# psoc4hvpaspm10 register map
Vendor: Infineon Technologies; Series: PSOC4HVPASPM10; File version: 1.0
CPU: CM0PLUS r0p1, little endian, MPU, no FPU, VTOR, 2 interrupt priority bits, 32 interrupts
Registers are 32-bit, read-write, reset 0x0 unless marked. A register's access mark holds for its fields unless they carry their own. Offsets are from the block's base; [hi:lo] are bit positions; lines under a group give offsets from that group; {n}, {i} and the like mark numbered series.

## LIN0 — LIN
Base 0x402D0000
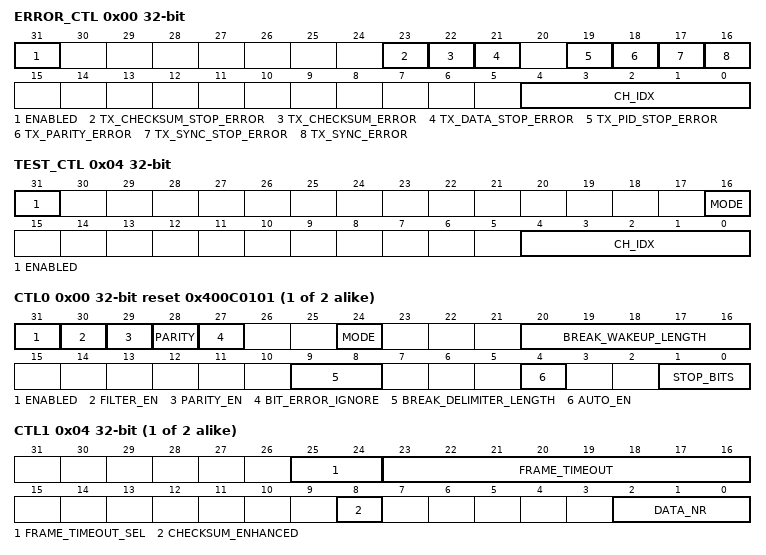
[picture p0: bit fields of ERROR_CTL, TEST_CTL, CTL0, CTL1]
0x00 ERROR_CTL — Error control
  [31] ENABLED — Error injection enable: '0': Disabled. '1': Enabled.
  [23] TX_CHECKSUM_STOP_ERROR — The checksum field STOP bits are inverted to '0'. At the receiver, this should result in INTR.RX_RESPONSE_FRAME_ERROR activation.
  [22] TX_CHECKSUM_ERROR — The checksum field is inverted. At the receiver, this should result in INTR.RX_RESPONSE_CHECKSUM_ERROR activation.
  [21] TX_DATA_STOP_ERROR — The data field STOP bits are inverted to '0'. At the receiver, this should result in INTR.RX_RESPONSE_FRAME_ERROR activation. Note: Used in UART mode.
  [19] TX_PID_STOP_ERROR — The PID field STOP bits are inverted to '0'. At the receiver, this should result in INTR.RX_HEADER_FRAME_ERROR activation.
  [18] TX_PARITY_ERROR — In LIN mode, the PID parity bit P[1] is inverted from !(ID[5] ^ ID[4] ^ ID[3] ^ ID[1]) to (ID[5] ^ ID[4] ^ ID[3] ^ ID[1]). At the receiver, this should result in INTR.RX_HEADER_PARITY_ERROR activation. In UART mode, a data field's parity bit is inverted.
  [17] TX_SYNC_STOP_ERROR — The synchronization field STOP bits are inverted to '0'. At the receiver, this should result in INTR.RX_HEADER_SYNC_ERROR or INTR.RX_HEADER_FRAME_ERROR activation.
  [16] TX_SYNC_ERROR — The synchronization field is changed from 0x55 to 0x00. At the receiver, this should result in INTR.RX_HEADER_SYNC_ERROR activation.
  [4:0] CH_IDX — Specifies the channel index of the channel to which HW injected channel transmitter errors applies.
0x04 TEST_CTL — Test control
  [31] ENABLED — Test enable: '0': Disabled. Functional mode. - tx_in[CH_IDX] = IOSS lin_tx_in[CH_IDX]. - tx_in[CH_NR-1] = IOSS lin_tx_in[CH_NR-1]. - rx_in[CH_IDX] = IOSS lin_rx_in[CH_IDX]. - rx_in[CH_NR-1] = IOSS lin_rx_in[CH_NR-1]. - lin_tx_out[CH_IDX] = tx_out[CH_IDX]. - lin_tx_out[CH_NR-1] = tx_out[CH_NR-1]. '1': Enabled. Test mode, specific test mode is specified by MODE.
  [16] MODE — Test mode: '0': Partial disconnect from IOSS. This mode's isolation allows for device test without relying on an external LIN transceiver. The IOSS 'tx' IO cell can be used to observe messages outside of the device. - tx_in[CH_IDX] = IOSS lin_tx_in[CH_IDX]. - tx_in[CH_NR-1] = IOSS lin_tx_in[CH_IDX]. - rx_in[CH_IDX] = IOSS lin_tx_in[CH_IDX]. - rx_in[CH_NR-1] = IOSS lin_tx_in[CH_IDX]. - lin_tx_out[CH_IDX] = tx_out[CH_IDX] & tx_out[CH_NR-1]. - lin_tx_out[CH_NR-1] = tx_out[CH_IDX] & tx_out[CH_NR-1]. '1': Full disconnect from IOSS (the IOSS/HSIOM should disconnect 'tx_out' from the 'tx' IO cell). This mode's isolation allows for device test without effecting an operational LIN cluster. - tx_in[CH_IDX] = lin_tx_out[CH_IDX]. - tx_in[CH_NR-1] = lin_tx_out[CH_IDX]. - rx_in[CH_IDX] = lin_tx_out[CH_IDX]. - rx_in[CH_NR-1] = lin_tx_out[CH_IDX]. - lin_tx_out[CH_IDX] = tx_out[CH_IDX] & tx_out[CH_NR-1]. - lin_tx_out[CH_NR-1] = tx_out[CH_IDX] & tx_out[CH_NR-1].
  [4:0] CH_IDX — Specifies the channel index of the channel to which test applies. The channel IO signals of channel indices CH_IDX and CH_NR-1 are connected as specified by MODE. CH_IDX should be in the range [0, CH_NR-2], as channel index CH_NR-1 is always involved in test and cannot be connected to itself. The test mode allows BOTH of the two connected channels to be tested. Note: this testing functionality simplifies SW development, but may also be used in the field to verify correct channel functionality.
{0x8000+0x100*i} CH[{i}] (i=0..1) group — LIN channel structure
  0x00 CTL0 reset 0x400C0101 — Control 0
    [31] ENABLED — Channel enable: '0': Disabled. If a channel is disabled, all non-retained MMIO registers (e.g. the TX_RX_STATUS, and INTR registers) have their fields reset to their default value. '1': Enabled.
    [30] FILTER_EN — RX filter (for 'lin_rx_in'): '0': No filter. '1': Median 3 (default value) operates on the last three 'lin_rx_in' values. The sequences '000', '001', '010' and '100' result in a filtered value '0'. The sequences '111', '110', '101' and '011' result in a filtered value '1'.
    [29] PARITY_EN — Parity generation enable: '0': Disabled. No parity bit is transferred. '1': Enabled. The parity bit is transferred after the last (most significant) data field bit. Note: Used in UART mode only.
    [28] PARITY — Parity mode: '0': Even parity: even number of '1' bits (including parity). '1': Odd parity. Note: Used in UART mode only.
    [27] BIT_ERROR_IGNORE — Specifies behavior on a detected bit error during header or response transmission: '0': Message transfer is aborted. '1': Message transfer is NOT aborted. Note: this field does NOT effect the reporting of the bit error through INTR/STATUS.TX_HEADER/RESPONSE_BIT_ERROR; i.e. bit errors are always reported.
    [24] MODE — Mode of operation: '0': LIN mode. '1': UART mode.
      0=LIN (LIN mode.); 1=UART (UART mode.)
    [20:16] BREAK_WAKEUP_LENGTH — Break/wakeup length (minus 1) in bit periods: '0': 1 bit period. ... '10': 11 bit periods (break length for slave nodes) ... '12': 13 bit periods (break length for master nodes) ... '30': 31 bit periods. '31': Illegal (should NOT be used!!!) This field is used for transmission/reception of BOTH break and wakeup signals. Note that these functions are mutually exclusive: - When CMD.TX_HEADER is '1', the field specifies the transmitted break field. - When CMD.TX_WAKEUP is '1', the field specifies the transmitted wakeup field. - When CMD.RX_HEADER is '1', the field specifies the to be received break field. - Otherwise, the field specifies the to be received wakeup field. Per the standard, the master wakeup duration is between 250 us and 5 ms. To support uncalibrated slaves, a slave has a detection threshold of 150 us (3 bit periods at 20 kbps). After transmission of a break or wakeup signal, the INTR.TX_BREAK_WAKEUP_DONE interrupt cause is activated. After reception of a wakeup signal, the INTR.RX_BREAK_WAKEUP_DONE interrupt cause is activated. To specify longer wakeup signals in terms of absolute time (us/ms rather than bit periods), the associated PERI clock divider value can be (temporarily) increased to make the LIN bit period longer. Note: entering bus sleep mode is achieved with the 'go-to-sleep' command.
    [9:8] BREAK_DELIMITER_LENGTH — In LIN mode, this field specifies the break delimiter length: (used in header transmission, not used in header reception). '0': 1 bit period. '1': 2 bit periods (default value). '2': 3 bit periods. '3': 4 bit periods. In UART mode, this field specifies the data field size: '0': 5 bit data field. '1': 6 bit data field. '2': 7 bit data field. '3': 8 bit data field. When the data field size is less than 8 bits, the most significant (unused) bits of the DATAx.DATAy[7:0] fields should be set to '0' for the transmitter.
    [4] AUTO_EN — LIN transceiver auto enable: '0': Disabled. '1': Enabled. The TX_RX_STATUS.EN_OUT field is controlled by HW.
    [1:0] STOP_BITS — STOP bit periods: '0': 1/2 bit period. '1': 1 bit period. '2': 1 1/2 bit period. '3': 2 bit periods. In LIN mode, this field should be set to '1' (the default value) . In UART mode, this field can be programmed as desired. Note: receiver STOP bit frame errors can only be detected if the number of STOP bit periods is 1 or more bit period.
  0x04 CTL1 (reset mask 0x3000000) — Control 1
    [25:24] FRAME_TIMEOUT_SEL — Specifies the frame timeout mode: '0': No timeout functionality (default value). '1': Frame mode: detects timeout from the start of break field to checksum field STOP bits (inclusive). The minimum FRAME_TIMEOUT value is 34+20 bit periods (header and a response with 1 data field). '2': Frame header mode: detects timeout from the start of break field to PID field STOP bits (inclusive). The minimum FRAME_TIMEOUT value is 34 bit periods (header). '3': Frame response mode: detects timeout from the PID field STOP bits (exclusive) to checksum field STOP bits (the response space is included in the frame response). The minimum FRAME_TIMEOUT value is 20 bit periods (response with 1 data field).
    [23:16] FRAME_TIMEOUT — Specifies the maximum allowed length (timeout value) for a frame, frame header or frame response in bit periods. The LIN specification prescribes to set the maximum length to 1.4x the nominal length (Theader_max = 1.4 x Theader_nom and Tresponse_max = 1.4 x Tresponse_nom). The nominal header length Theader_nom is 34 bit periods and the nominal response length Tresponse_nom is 10 * (data_nr + 1) bit periods (data_nr is the number of data fields) Note: the LIN specification specifies the following: 'Tools and tests shall check the Tframe_max (= Theader_max + Tresponse_max). Nodes shall not check this time. The receiving node of the frame shall accept the frame up to the next frame slot (i.e. next break field), even if it is longer then Tframe_max).'
    [8] CHECKSUM_ENHANCED — Checksum mode: '0': Classic mode. PID field is NOT included in the checksum calculation. '1': Enhanced mode. PID field is included in the checksum calculation. This mode requires special attention when the master node transmits the header and a (different) slave node transmits the response: the slave node will use the calculated partial checksum over the received PID field as a starting point for the calculation over the to be transmitted data fields. Note: If the frame identifier ID[5:0] is 0x3c or 0x3d, the classic mode will ALWAYS be used for transmission and assumed for reception, independent of the CHECKSUM_ENHANCED value.
    [2:0] DATA_NR — Number of data fields (minus 1) in the response (not including the checksum): '0': 1 data field. '1': 2 data fields. ... '7': 8 data fields. Note: master and slave nodes need to agree upon the number of data fields before message transfer. In RX_RESPONSE case, When PID (header) is received, firmware has the time of one response data byte, to modify CTL1.DATA_NR.
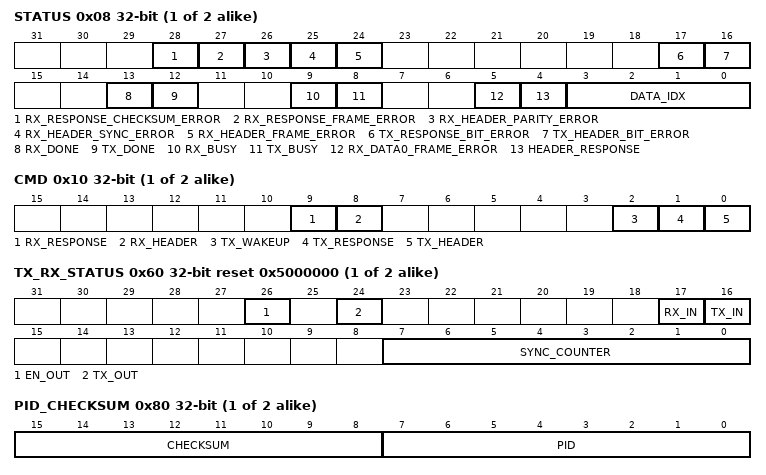
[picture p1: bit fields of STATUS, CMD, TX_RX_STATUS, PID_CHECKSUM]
  0x08 STATUS ro
    [28] RX_RESPONSE_CHECKSUM_ERROR — Copy of INTR.RX_RESPONSE_CHECKSUM_ERROR.
    [27] RX_RESPONSE_FRAME_ERROR — Copy of INTR.RX_RESPONSE_FRAME_ERROR.
    [26] RX_HEADER_PARITY_ERROR — Copy of INTR.RX_HEADER_PARITY_ERROR.
    [25] RX_HEADER_SYNC_ERROR — Copy of INTR.RX_HEADER_SYNC_ERROR.
    [24] RX_HEADER_FRAME_ERROR — Copy of INTR.RX_HEADER_FRAME_ERROR.
    [17] TX_RESPONSE_BIT_ERROR — Copy of INTR.TX_RESPONSE_BIT_ERROR.
    [16] TX_HEADER_BIT_ERROR — Copy of INTR.TX_HEADER_BIT_ERROR.
    [13] RX_DONE — Receiver done: - Set to '0' on the start of a new command. - Set to '1' on successful completion of the following command sequences (if CTL.AUTO_EN is '1', this includes the 4-bit period external transceiver disable post-amble): - RX_HEADER, RX_RESPONSE. - TX_HEADER, RX_RESPONSE.
    [12] TX_DONE — Transmitter done: - Set to '0' on the start of a new command. - Set to '1' on successful completion of the following command sequences (if CTL.AUTO_EN is '1', this includes the 4-bit period external transceiver disable post-amble): - TX_HEADER. - TX_HEADER, TX_RESPONSE. - RX_HEADER, TX_RESPONSE. - TX_WAKEUP.
    [9] RX_BUSY — Receiver busy. - Set to '1' on the start of the following commands: RX_HEADER, RX_RESPONSE. in RX_HEADER case, set at Break filed rising edge. in RX_RESPONSE case, set at the start bit falling edge in the first response data byte. - Set to '0' on successful completion of previous commands or when an error is detected. In the successful completion case, RX_BUSY is updated one cycle after RX_DONE.
    [8] TX_BUSY — Transmitter busy. - Set to '1' on the start of the following commands: TX_HEADER, TX_RESPONSE, TX_WAKEUP. - Set to '0' on successful completion of previous commands or when an error is detected. In the successful completion case, TX_BUSY is updated one cycle after TX_DONE. In 'TX_HEADER, RX_RESPONSE' case, set to '0' at the start bit falling edge in the first response data byte, after header transmission
    [5] RX_DATA0_FRAME_ERROR — Frame response, first data field frame error. HW sets this field to '1' when the received STOP bits of the first response data field have an unexpected value (only after a RX_HEADER command), and this data byte is 0x00. HW clears this field to '0' at the falling edge of SYNC start bit (after INTR.RX_HEADER_BREAK_WAKEUP_DONE). This field is used together with INTR.RX_RESPONSE_FRAME_ERROR to distinguish 'no response', 'error response' and 'correct response' scenarios. Note: The ongoing message transfer is NOT aborted.
    [4] HEADER_RESPONSE — Frame header / response identifier (only valid when TX_BUSY or RX_BUSY is '1'): '0': Frame header being transferred. '1': Frame response being transferred.
    [3:0] DATA_IDX — Number of transferred data and checksum fields in the response (also acts as an index/address into response data field and checksum field registers (DATA0, DATA1, PID_CHECKSUM)) : '0': No data fields transferred. '1': Data field 1 transferred. ... '7': Data fields 1, 2, 3, ... and 7 transferred. '8': Data fields 1, 2, 3, ... and 8 transferred. '9': Data fields 1, 2, 3, ..., 8 and checksum field transferred. '10'-'15': Unused. Set to '0' on the start of a TX_HEADER or RX_HEADER command.
  0x10 CMD — Command
    [9] RX_RESPONSE write-1-sets — SW sets this field to '1' to receive a response. HW sets this field to '0' on successful completion of ANY of the legal command sequences (NOT set to '0' when an error is detected). The response is received when the checksum field STOP bits are received (INTR.RX_RESPONSE_DONE).
    [8] RX_HEADER write-1-sets — SW sets this field to '1' to receive a header. HW sets this field to '0' on successful completion of the ANY of the legal command sequences (NOT set to '0' when an error is detected in LIN mode). The header is received when the PID field STOP bits are received (INTR.RX_HEADER_DONE). Typically, a slave node SW sets both RX_HEADER and RX_RESPONSE to '1', anticipating a transfer of a response from the master node to this slave node. After receipt of the header PID field (INTR.RX_HEADER_PID_DONE is activated), the slave node may decide to set TX_RESPONSE to '1' (which has a higher priority than RX_RESPONSE) to transmit a response. the Break detection is performed regardless of CMD.RX_HEADER. INTR.RX_BREAK_WAKEUP_DONE will trigger at LIN_RX rising edge, when the low pulse meet CTL0.BREAK_WAKEUP_LENGTH. when Break is detected, HW check CMD.RX_HEADER before entering SYNC byte processing state. when RX_HEADER is cleared, SW has at least 11 bit times to set RX_HEADER again, before next Break is detected (RX_BREAK_WAKEUP_DONE). in this case, there is no gap, Break will never be missed. In UART mode, a single data field in received (in DATA0.DATA1). HW set this field to '0' when the data field is received, or when an error is detected.
    [2] TX_WAKEUP write-1-sets — SW sets this field to '1' to transmit a wakeup signal. HW sets this field to '0' on successful completion of ANY of the legal command sequences (also set to '0' when an error is detected). The command generates CTL.BREAK_WAKEUP_LENGTH bit periods in the dominant state (low/'0') and transitions to the recessive state (high/'1') (INTR.TX_WAKEUP_DONE).
    [1] TX_RESPONSE write-1-sets — SW sets this field to '1' to transmit a response. HW sets this field to '0' on successful completion of ANY of the legal command sequences (also set to '0' when an error is detected). The response is transmitted when the checksum field STOP bits are transmitted (INTR.TX_RESPONSE_DONE).
    [0] TX_HEADER write-1-sets — SW sets this field to '1' to transmit a header. HW sets this field to '0' on successful completion of ANY of the following legal command sequences (also set to '0' when an error is detected): - TX_HEADER - TX_HEADER, TX_RESPONSE. - TX_HEADER, RX_RESPONSE. - RX_HEADER, TX_RESPONSE. - RX_HEADER, RX_RESPONSE. - TX_WAKEUP. The header is transmitted when the PID field STOP bits are transmitted (INTR.TX_HEADER_DONE). HW sets this field to '1', when the 'tr_cmd_tx_header' input trigger is activated. This allows for time triggered LIN message transfer. HW driven time triggered transfer eliminates the jitter that is typically associated with SW driven transfer. In UART mode, a single data field (DATA0.DATA1) is transmitted.
  0x60 TX_RX_STATUS reset 0x5000000 (reset mask 0x5000000)
    [26] EN_OUT — LIN transceiver enable ('en_out', 'lin_en_out'). This field controls the enable (or low active sleep enable) of the external transceiver: '0': Disabled. '1': Enabled. If CTL.AUTO_EN is '0', SW controls this field to enable the external transceiver. If CTL.AUTO_EN is '1', HW controls this field to enable the external transceiver: - Before a legal command sequence, HW sets this field to '1', if it is '0'. The start of the command sequence is effectively postponed by a 4-bit period preamble. - After a legal command sequence, HW clears this field to '0'. The end of the command sequence is effectively postponed by a 4-bit period postamble. Note: external transceivers require a 'power up' or 'power down' period of 1 or 2 bit periods, so a 4-bit period suffices for all known transceivers.
    [24] TX_OUT ro — LIN transmitter output ('tx_out', 'lin_tx_out').
    [17] RX_IN ro — LIN receiver input ('rx_in', 'lin_rx_in' in functional mode).
    [16] TX_IN ro — LIN transmitter input ('tx_in', 'lin_tx_in' in functional mode). TX_IN and RX_IN can be used to determine a wakeup source. Note that wakeup source detection relies on the external transceiver functionality.
    [7:0] SYNC_COUNTER ro — Synchronization counter in LIN channel clock periods. After the receipt of a synchronization field, this fields reflects the duration of the synchronization field. Ideally, SYNC_COUNTER = 8*16 = 128 (the synchronization fields consists of eight bit period of 16 LIN channel clock periods each). - If SYNC_COUNTER is less than 128, the LIN channel clock is too slow and the PERI/PCLK divider value should be decreased. - If SYNC_COUNTER is greater than 128, the LIN channel clock is too fast and the PERI/PCLK divider value should be increased. The biggest master-slave clock discrepancy occurs when the master is slow and the slave is fast or vice versa. At a 0.5 percent master inaccuracy and a 14 percent slave inaccuracy, this results in the extreme synchronization values of (.86 * 128) / 1.005 = 109.5 and (1.14 *128) / 0.995 = 146.6. We add a little margin for a valid range of [106, 152]. Note: Only slave nodes with imprecise clocks require clock resynchronization. Master and slave nodes with precise clocks do NOT require clock resynchronization.
  0x80 PID_CHECKSUM reset not defined — PID and checksum
    [15:8] CHECKSUM ro — Checksum. Transmission: HW calculated checksum (SW does not need to calculate the checksum) over the transmitted PID field (optional per CTL.CHECKSUM_ENHANCED) and data fields. Reception: Received checksum. Note that in case of a RX_CHECKSUM_ERROR, SW can use the received PID field and the received data fields to calculate the correct checksum value.
    [7:0] PID — Header protected identifier (PID). - Bits 5 down to 0: frame identifier ID[5:0]. Frame identifier 0x3c is for a 'master request' frame, 0x3d is for a 'slave response' frame, 0x3e and 0x3f are for future LIN enhancements. Frame identifier ID[5:4] is optionally used for length control; i.e. specifies the number of response data fields. - Bits 1 down to 0: parity bits P[1] and P[0]. - P[1] = ! (ID[5] ^ ID[4] ^ ID[3] ^ ID[1]) - P[0] = (ID[4] ^ ID[2] ^ ID[1] ^ ID[0]) Transmission: To be transmitted PID field. SW needs to calculate the PID field parity bits P[1] and P[0]. Reception: Received PID field. Slave node SW uses the PID field to determine how to handle the response for a received frame header: TX_RESPONSE or RX_RESPONSE.
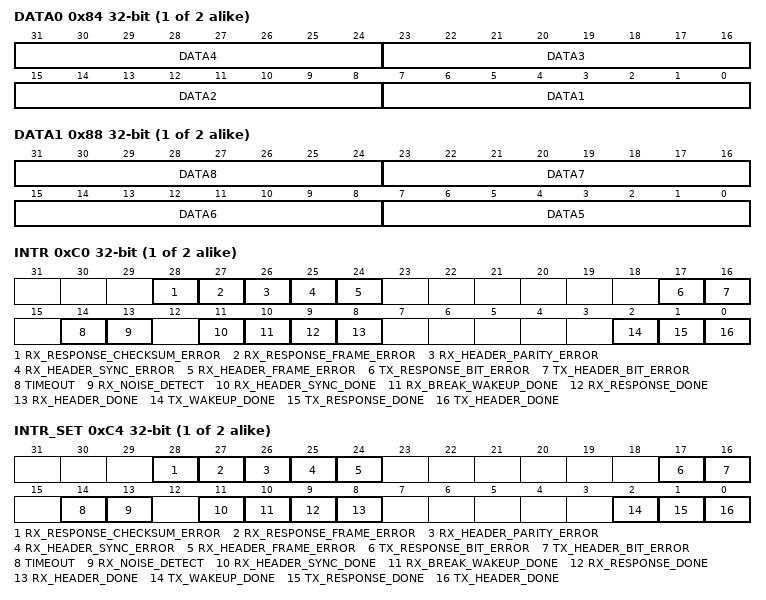
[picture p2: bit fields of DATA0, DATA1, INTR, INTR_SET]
  0x84 DATA0 reset not defined — Response data 0
    [31:24] DATA4 — Data field 4.
    [23:16] DATA3 — Data field 3.
    [15:8] DATA2 — Data field 2.
    [7:0] DATA1 — Data field 1. Transmission: To be transmitted data field. SW provides data field. Reception: Received data field. SW uses the data field.
  0x88 DATA1 reset not defined — Response data 1
    [8n-33:8n-40] DATA{n} (n=5..8) — Data field {n}.
  0xC0 INTR — Interrupt
    [28] RX_RESPONSE_CHECKSUM_ERROR write-1-clears — HW sets this field to '1', when the calculated checksum over the received PID and data fields is not the same as the received checksum. Note: The ongoing message transfer is aborted (INTR.RX_RESPONSE_DONE is NOT activated) and the TX_HEADER, TX_RESPONSE and TX_WAKEUP commands are set to '0'.
    [27] RX_RESPONSE_FRAME_ERROR write-1-clears — HW sets this field to '1', when the received START or STOP bits have an unexpected value (during response reception). HW does NOT use this field for the STOP bits of the first data field after a RX_HEADER command, if the received data byte is 0x00. (STATUS.RX_DATA0_FRAME_ERROR is used instead). Note: The ongoing message transfer is aborted (INTR.RX_RESPONSE_DONE is NOT activated) and the TX_HEADER, TX_RESPONSE and TX_WAKEUP commands are set to '0'.
    [26] RX_HEADER_PARITY_ERROR write-1-clears — HW sets this field to '1', when the received PID field has a parity error. Note: The ongoing message transfer is aborted (INTR.RX_PID_DONE is NOT activated) and the TX_HEADER, TX_RESPONSE and TX_WAKEUP commands are set to '0'. +G119 HW sets this field to '1', when the received data field has a parity error (when CTL0.PARITY_EN is '1').
    [25] RX_HEADER_SYNC_ERROR write-1-clears — HW sets this field to '1', when the received synchronization field is not received within the synchronization counter range [106, 152] (see TX_RX_STATUS.SYNC_COUNTER). Note: The ongoing message transfer is aborted (INTR.RX_HEADER_SYNC_DONE is NOT activated) and the TX_HEADER, TX_RESPONSE and TX_WAKEUP commands are set to '0'.
    [24] RX_HEADER_FRAME_ERROR write-1-clears — HW sets this field to '1', when the received START or STOP bits have an unexpected value (during header reception). Note: The ongoing message transfer is aborted (INTR.RX_HEADER_DONE is NOT activated) and the TX_HEADER, TX_RESPONSE and TX_WAKEUP commands are set to '0'. Note: Used in UART mode.
    [17] TX_RESPONSE_BIT_ERROR write-1-clears — HW sets this field to '1', when a transmitted 'lin_tx_out' value does NOT match a received 'lin_rx_in' value (during response transmission). The match is performed for the data fields and the checksum field (for the START bit, data Byte and STOP bit). Note: When CTL.BIT_ERROR_IGNORE is '0', the ongoing message transfer is aborted (INTR.TX_RESPONSE_DONE is NOT activated) and the TX_HEADER, TX_RESPONSE and TX_WAKEUP commands are set to '0'.
    [16] TX_HEADER_BIT_ERROR write-1-clears — HW sets this field to '1', when a transmitted 'lin_tx_out' value does NOT match a received 'lin_rx_in' value (during header transmission). This specific test allows for delay through the external transceiver. This mismatch is an indication of bus collisions on the LIN line. The match is performed for the Wakeup, Break, SYNC and the PID fields (for the START bit, data Byte and STOP bit). Note: When CTL.BIT_ERROR_IGNORE is '0', the ongoing message transfer is aborted (INTR.TX_HEADER_DONE is NOT activated) and the TX_HEADER, TX_RESPONSE and TX_WAKEUP commands are set to '0'. Note: Used in UART mode.
    [14] TIMEOUT write-1-clears — HW sets this field to '1', when a frame, frame header or frame response timeout is detected (per CTL.FRAME_TIMEOUT_SEL). Note: The ongoing frame transfer is NOT aborted.
    [13] RX_NOISE_DETECT write-1-clears — HW sets this field to '1', when isolated '0' or '1' 'in_rx_in' values are observed or when during sampling the last three 'lin_rx_in' values do NOT all have the same value. This mismatch is an indication of noise on the LIN line. Note: The ongoing frame transfer is NOT aborted. Note: Used in UART mode.
    [11] RX_HEADER_SYNC_DONE write-1-clears — HW sets this field to '1', when a synchronization field is received (including trailing STOP bits).
    [10] RX_BREAK_WAKEUP_DONE write-1-clears — HW sets this field to '1', when a break or wakeup signal is received (per CTL.BREAK_WAKEUP_LENGTH). This cause is activated on a transition from dominant/'0' state to recessive/'1' state; i.e. at the end of the wakeup signal. The break or wakeup detection is always enabled, regardless of CMD register setting.
    [9] RX_RESPONSE_DONE write-1-clears — HW sets this field to '1', when a frame response (data fields and checksum field) is received (the CMD.RX_RESPONSE is completed). If CTL.AUTO_EN is '1', this includes the 4-bit period external transceiver disable post-amble. Note: activation implies that RX_RESPONSE_FRAME_ERROR and RX_RESPONSE_CHECKSUM_ERROR are not activated during response reception
    [8] RX_HEADER_DONE write-1-clears — HW sets this field to '1', when a frame header (break field, synchronization field and PID field) is received (the CMD.RX_HEADER is completed). Specifically: - When followed by CMD.TX_RESPONSE or CMD.RX_RESPONSE, this field is set to '1' after completion of the frame header transfer. - When not followed by a response command, this field is set to '1' after completion of the frame header transfer. If CTL.AUTO_EN is '1', this includes the 4-bit period external transceiver disable post-amble. Note: used in UART mode.
    [2] TX_WAKEUP_DONE write-1-clears — HW sets this field to '1', when a wakeup signal is transmitted (per CTL.BREAK_WAKEUP_LENGTH). This cause is activated on a transition from dominant/'0' state to recessive/'1' state; i.e. at the end of the wakeup signal.
    [1] TX_RESPONSE_DONE write-1-clears — HW sets this field to '1', when a frame response (data fields and checksum field) is transmitted (the CMD.TX_RESPONSE is completed). If CTL.AUTO_EN is '1', this includes the 4-bit period external transceiver disable post-amble.
    [0] TX_HEADER_DONE write-1-clears — HW sets this field to '1', when a frame header (break field, synchronization field and PID field) is transmitted (the CMD.TX_HEADER is completed). Specifically: - When followed by CMD.TX_RESPONSE or CMD.RX_RESPONSE, this field is set to '1' after completion of the frame header transfer. - When not followed by a response command, this field is set to '1' after completion of the frame header transfer. If CTL.AUTO_EN is '1', this includes the 4-bit period external transceiver disable post-amble. Note: used in UART mode.
  0xC4 INTR_SET — Interrupt set
    [28] RX_RESPONSE_CHECKSUM_ERROR write-1-sets — Write INTR_SET field with '1' to set corresponding INTR field (a write of '0' has no effect).
    [27] RX_RESPONSE_FRAME_ERROR write-1-sets — Write INTR_SET field with '1' to set corresponding INTR field (a write of '0' has no effect).
    [26] RX_HEADER_PARITY_ERROR write-1-sets — Write INTR_SET field with '1' to set corresponding INTR field (a write of '0' has no effect).
    [25] RX_HEADER_SYNC_ERROR write-1-sets — Write INTR_SET field with '1' to set corresponding INTR field (a write of '0' has no effect).
    [24] RX_HEADER_FRAME_ERROR write-1-sets — Write INTR_SET field with '1' to set corresponding INTR field (a write of '0' has no effect).
    [17] TX_RESPONSE_BIT_ERROR write-1-sets — Write INTR_SET field with '1' to set corresponding INTR field (a write of '0' has no effect).
    [16] TX_HEADER_BIT_ERROR write-1-sets — Write INTR_SET field with '1' to set corresponding INTR field (a write of '0' has no effect).
    [14] TIMEOUT write-1-sets — Write INTR_SET field with '1' to set corresponding INTR field (a write of '0' has no effect).
    [13] RX_NOISE_DETECT write-1-sets — Write INTR_SET field with '1' to set corresponding INTR field (a write of '0' has no effect).
    [11] RX_HEADER_SYNC_DONE write-1-sets — Write INTR_SET field with '1' to set corresponding INTR field (a write of '0' has no effect).
    [10] RX_BREAK_WAKEUP_DONE write-1-sets — Write INTR_SET field with '1' to set corresponding INTR field (a write of '0' has no effect).
    [9] RX_RESPONSE_DONE write-1-sets — Write INTR_SET field with '1' to set corresponding INTR field (a write of '0' has no effect).
    [8] RX_HEADER_DONE write-1-sets — Write INTR_SET field with '1' to set corresponding INTR field (a write of '0' has no effect).
    [2] TX_WAKEUP_DONE write-1-sets — Write INTR_SET field with '1' to set corresponding INTR field (a write of '0' has no effect).
    [1] TX_RESPONSE_DONE write-1-sets — Write INTR_SET field with '1' to set corresponding INTR field (a write of '0' has no effect).
    [0] TX_HEADER_DONE write-1-sets — Write INTR_SET field with '1' to set corresponding INTR field (a write of '0' has no effect).
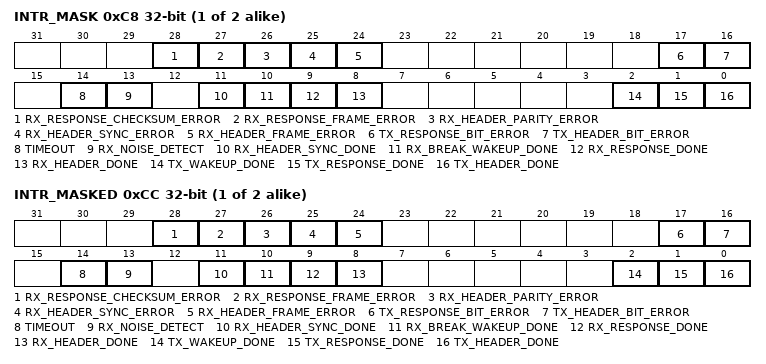
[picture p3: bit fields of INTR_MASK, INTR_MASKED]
  0xC8 INTR_MASK — Interrupt mask
    [28] RX_RESPONSE_CHECKSUM_ERROR — Mask for corresponding field in INTR register.
    [27] RX_RESPONSE_FRAME_ERROR — Mask for corresponding field in INTR register.
    [26] RX_HEADER_PARITY_ERROR — Mask for corresponding field in INTR register.
    [25] RX_HEADER_SYNC_ERROR — Mask for corresponding field in INTR register.
    [24] RX_HEADER_FRAME_ERROR — Mask for corresponding field in INTR register.
    [17] TX_RESPONSE_BIT_ERROR — Mask for corresponding field in INTR register.
    [16] TX_HEADER_BIT_ERROR — Mask for corresponding field in INTR register.
    [14] TIMEOUT — Mask for corresponding field in INTR register.
    [13] RX_NOISE_DETECT — Mask for corresponding field in INTR register.
    [11] RX_HEADER_SYNC_DONE — Mask for corresponding field in INTR register.
    [10] RX_BREAK_WAKEUP_DONE — Mask for corresponding field in INTR register.
    [9] RX_RESPONSE_DONE — Mask for corresponding field in INTR register.
    [8] RX_HEADER_DONE — Mask for corresponding field in INTR register.
    [2] TX_WAKEUP_DONE — Mask for corresponding field in INTR register.
    [1] TX_RESPONSE_DONE — Mask for corresponding field in INTR register.
    [0] TX_HEADER_DONE — Mask for corresponding field in INTR register.
  0xCC INTR_MASKED ro — Interrupt masked
    [28] RX_RESPONSE_CHECKSUM_ERROR — Logical AND of corresponding INTR and INTR_MASK fields.
    [27] RX_RESPONSE_FRAME_ERROR — Logical AND of corresponding INTR and INTR_MASK fields.
    [26] RX_HEADER_PARITY_ERROR — Logical AND of corresponding INTR and INTR_MASK fields.
    [25] RX_HEADER_SYNC_ERROR — Logical AND of corresponding INTR and INTR_MASK fields.
    [24] RX_HEADER_FRAME_ERROR — Logical AND of corresponding INTR and INTR_MASK fields.
    [17] TX_RESPONSE_BIT_ERROR — Logical AND of corresponding INTR and INTR_MASK fields.
    [16] TX_HEADER_BIT_ERROR — Logical AND of corresponding INTR and INTR_MASK fields.
    [14] TIMEOUT — Logical AND of corresponding INTR and INTR_MASK fields.
    [13] RX_NOISE_DETECT — Logical AND of corresponding INTR and INTR_MASK fields.
    [11] RX_HEADER_SYNC_DONE — Logical AND of corresponding INTR and INTR_MASK fields.
    [10] RX_BREAK_WAKEUP_DONE — Logical AND of corresponding INTR and INTR_MASK fields.
    [9] RX_RESPONSE_DONE — Logical AND of corresponding INTR and INTR_MASK fields.
    [8] RX_HEADER_DONE — Logical AND of corresponding INTR and INTR_MASK fields.
    [2] TX_WAKEUP_DONE — Logical AND of corresponding INTR and INTR_MASK fields.
    [1] TX_RESPONSE_DONE — Logical AND of corresponding INTR and INTR_MASK fields.
    [0] TX_HEADER_DONE — Logical AND of corresponding INTR and INTR_MASK fields.
